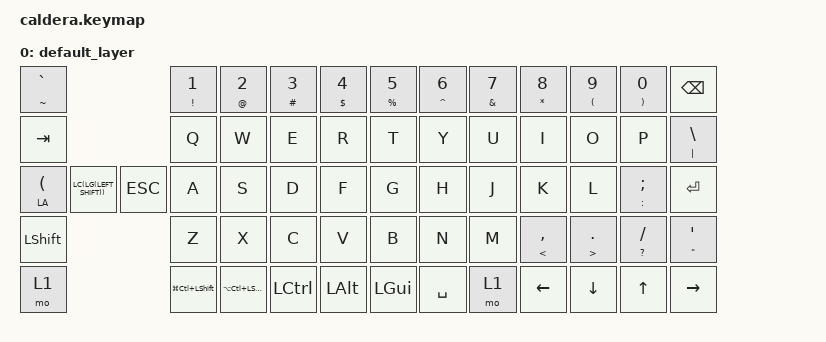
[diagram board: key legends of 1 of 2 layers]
#include <behaviors.dtsi>
#include <dt-bindings/zmk/bt.h>
#include <dt-bindings/zmk/keys.h>

/ {
    keymap {
        compatible = "zmk,keymap";

        default_layer {
            // ---------------------------------------------------------------------------------
            // |   `  |  1  |  2  |  3  |  4  |  5  |     |  6  |  7  |  8  |  9  |  0  | BKSP |
            // |  TAB |  Q  |  W  |  E  |  R  |  T  |     |  Y  |  U  |  I  |  O  |  P  |  \   |
            // | CAPS |  A  |  S  |  D  |  F  |  G  |     |  H  |  J  |  K  |  L  |  ;  |  ENT |
            // | SHFT |  Z  |  X  |  C  |  V  |  B  |     |  N  |  M  |  ,  |  .  |  /  | APOS |
            // | CTRL | ALT | GUI | SPC | SPC | SPC |     | SPC | LOW |LARW |DARW |UARW | RARW |

            bindings = <
&mt TILDE GRAVE                 &mt EXCL N1             &mt AT N2               &mt HASH N3  &mt DOLLAR N4  &mt PERCENT N5    &mt CARET N6  &mt AMPS N7  &mt ASTERISK N8      &mt LEFT_PARENTHESIS N9  &mt RIGHT_PARENTHESIS N0  &kp BSPC
&kp TAB                         &kp Q                   &kp W                   &kp E        &kp R          &kp T             &kp Y         &kp U        &kp I                &kp O                    &kp P                     &mt PIPE BSLH
&mt LA(LC(LG(LEFT_SHIFT))) ESC  &kp A                   &kp S                   &kp D        &kp F          &kp G             &kp H         &kp J        &kp K                &kp L                    &mt COLON SEMI            &kp RET
&kp LSHFT                       &kp Z                   &kp X                   &kp C        &kp V          &kp B             &kp N         &kp M        &mt LESS_THAN COMMA  &mt GREATER_THAN DOT     &mt QUESTION SLASH        &mt DOUBLE_QUOTES APOS
&mo 1                           &kp LG(LC(LEFT_SHIFT))  &kp LA(LC(LEFT_SHIFT))  &kp LCTRL    &kp LEFT_ALT   &kp LGUI          &kp SPACE     &mo 1        &kp LEFT_ARROW       &kp DOWN_ARROW           &kp UP_ARROW              &kp RIGHT_ARROW
            >;
        };

        lower_layer {
            // ------------------------------------------------------------------------------------------------------------
            // |       |  BT1  |  BT2  |  BT3  |  BT4  |  BT5  |          |       |       |       |       |       | BTCLR |
            // |       |       |       |       |       |       |          |       |       |       |       |       |       |
            // |       |       |       | LPAR  | RPAR  |       |          |       | LBKT  | RBKT  |       |       |       |
            // |       |       |       |       |       |       |          |       |       |       |       |       |       |

            bindings = <
&bt BT_CLR  &bt BT_SEL 0  &bt BT_SEL 1  &bt BT_SEL 2  &bt BT_SEL 3  &bt BT_SEL 4    &bt BT_CLR  &trans    &trans    &trans     &trans     &kp DEL
&trans      &kp F1        &kp F2        &kp F3        &kp F4        &kp F5          &kp F6      &kp F7    &kp F8    &kp F9     &trans     &trans
&trans      &trans        &trans        &kp LPAR      &kp RPAR      &trans          &trans      &kp LBKT  &kp RBKT  &kp MINUS  &kp EQUAL  &trans
&trans      &trans        &trans        &trans        &trans        &trans          &trans      &trans    &trans    &trans     &trans     &trans
            >;
        };
    };
};
